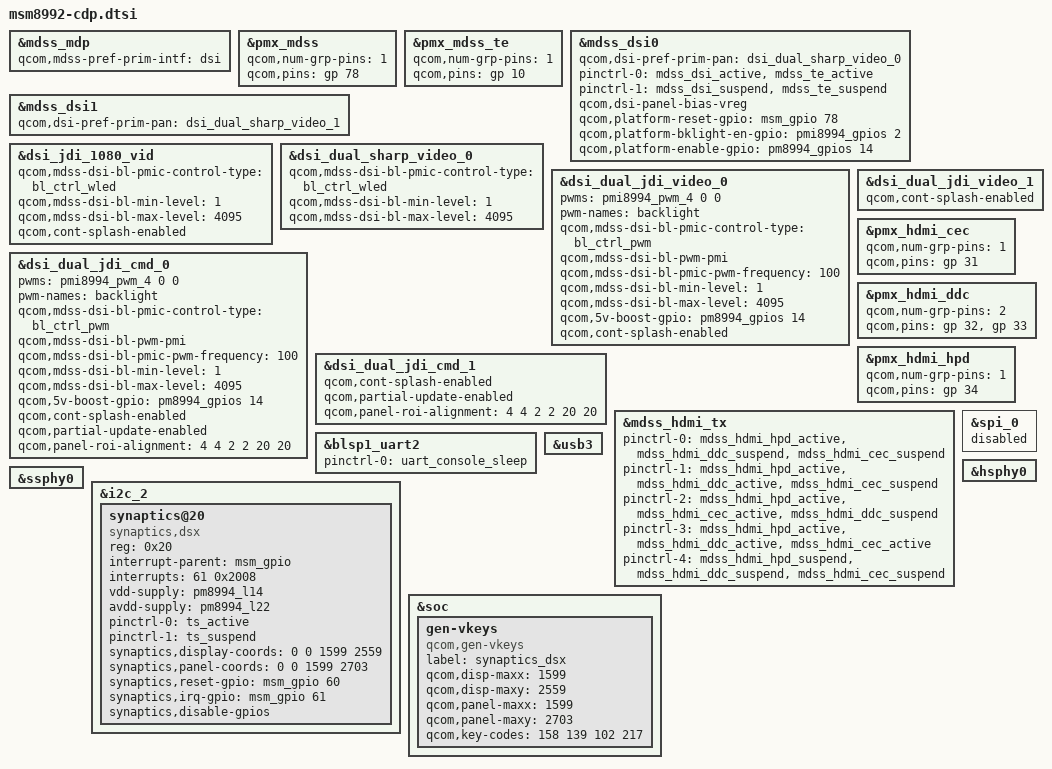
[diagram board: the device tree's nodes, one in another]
/* Copyright (c) 2014, The Linux Foundation. All rights reserved.
 *
 * This program is free software; you can redistribute it and/or modify
 * it under the terms of the GNU General Public License version 2 and
 * only version 2 as published by the Free Software Foundation.
 *
 * This program is distributed in the hope that it will be useful,
 * but WITHOUT ANY WARRANTY; without even the implied warranty of
 * MERCHANTABILITY or FITNESS FOR A PARTICULAR PURPOSE.  See the
 * GNU General Public License for more details.
 */

#include "msm8992-pinctrl.dtsi"

#include "dsi-panel-sharp-dualmipi0-wqxga-video.dtsi"
#include "dsi-panel-sharp-dualmipi1-wqxga-video.dtsi"
#include "dsi-panel-jdi-dualmipi0-video.dtsi"
#include "dsi-panel-jdi-dualmipi1-video.dtsi"
#include "dsi-panel-jdi-dualmipi0-cmd.dtsi"
#include "dsi-panel-jdi-dualmipi1-cmd.dtsi"
#include "dsi-panel-nt35597-wqxga-video.dtsi"
#include "dsi-panel-nt35597-wqxga-cmd.dtsi"
#include "dsi-panel-jdi-1080p-video.dtsi"

&mdss_mdp {
	qcom,mdss-pref-prim-intf = "dsi";
};

&pmx_mdss {
	qcom,num-grp-pins = <1>;
	qcom,pins = <&gp 78>;
};

&pmx_mdss_te {
	qcom,num-grp-pins = <1>;
	qcom,pins = <&gp 10>;
};

&mdss_dsi0 {
	qcom,dsi-pref-prim-pan = <&dsi_dual_sharp_video_0>;
	pinctrl-names = "mdss_default", "mdss_sleep";
	pinctrl-0 = <&mdss_dsi_active &mdss_te_active>;
	pinctrl-1 = <&mdss_dsi_suspend &mdss_te_suspend>;
	qcom,dsi-panel-bias-vreg;
	qcom,platform-reset-gpio = <&msm_gpio 78 0>;
	qcom,platform-bklight-en-gpio = <&pmi8994_gpios 2 0>;
	qcom,platform-enable-gpio = <&pm8994_gpios 14 0>;
};

&mdss_dsi1 {
	qcom,dsi-pref-prim-pan = <&dsi_dual_sharp_video_1>;
};

&dsi_jdi_1080_vid {
	qcom,mdss-dsi-bl-pmic-control-type = "bl_ctrl_wled";
	qcom,mdss-dsi-bl-min-level = <1>;
	qcom,mdss-dsi-bl-max-level = <4095>;
	qcom,cont-splash-enabled;
};

&dsi_dual_sharp_video_0 {
	qcom,mdss-dsi-bl-pmic-control-type = "bl_ctrl_wled";
	qcom,mdss-dsi-bl-min-level = <1>;
	qcom,mdss-dsi-bl-max-level = <4095>;
};

&dsi_dual_jdi_video_0 {
	pwms = <&pmi8994_pwm_4 0 0>;
	pwm-names = "backlight";
	qcom,mdss-dsi-bl-pmic-control-type = "bl_ctrl_pwm";
	qcom,mdss-dsi-bl-pwm-pmi;
	qcom,mdss-dsi-bl-pmic-pwm-frequency = <100>;
	qcom,mdss-dsi-bl-min-level = <1>;
	qcom,mdss-dsi-bl-max-level = <4095>;
	qcom,5v-boost-gpio = <&pm8994_gpios 14 0>;
	qcom,cont-splash-enabled;
};

&dsi_dual_jdi_video_1 {
	qcom,cont-splash-enabled;
};

&dsi_dual_jdi_cmd_0 {
	pwms = <&pmi8994_pwm_4 0 0>;
	pwm-names = "backlight";
	qcom,mdss-dsi-bl-pmic-control-type = "bl_ctrl_pwm";
	qcom,mdss-dsi-bl-pwm-pmi;
	qcom,mdss-dsi-bl-pmic-pwm-frequency = <100>;
	qcom,mdss-dsi-bl-min-level = <1>;
	qcom,mdss-dsi-bl-max-level = <4095>;
	qcom,5v-boost-gpio = <&pm8994_gpios 14 0>;
	qcom,cont-splash-enabled;
	qcom,partial-update-enabled;
	qcom,panel-roi-alignment = <4 4 2 2 20 20>;
};

&dsi_dual_jdi_cmd_1 {
	qcom,cont-splash-enabled;
	qcom,partial-update-enabled;
	qcom,panel-roi-alignment = <4 4 2 2 20 20>;
};

&pmx_hdmi_cec {
	qcom,num-grp-pins = <1>;
	qcom,pins = <&gp 31>;
};

&pmx_hdmi_ddc {
	qcom,num-grp-pins = <2>;
	qcom,pins = <&gp 32>, <&gp 33>;
};

&pmx_hdmi_hpd {
	qcom,num-grp-pins = <1>;
	qcom,pins = <&gp 34>;
};

&mdss_hdmi_tx {
	pinctrl-names = "hdmi_hpd_active", "hdmi_ddc_active",
				"hdmi_cec_active", "hdmi_active",
				"hdmi_sleep";
	pinctrl-0 = <&mdss_hdmi_hpd_active &mdss_hdmi_ddc_suspend
						&mdss_hdmi_cec_suspend>;
	pinctrl-1 = <&mdss_hdmi_hpd_active &mdss_hdmi_ddc_active
						&mdss_hdmi_cec_suspend>;
	pinctrl-2 = <&mdss_hdmi_hpd_active &mdss_hdmi_cec_active
						&mdss_hdmi_ddc_suspend>;
	pinctrl-3 = <&mdss_hdmi_hpd_active &mdss_hdmi_ddc_active
						&mdss_hdmi_cec_active>;
	pinctrl-4 = <&mdss_hdmi_hpd_suspend &mdss_hdmi_ddc_suspend
						&mdss_hdmi_cec_suspend>;
};
&blsp1_uart2 {
	status= "ok";
	pinctrl-names = "default";
	pinctrl-0 = <&uart_console_sleep>;
};

&spi_0 {
	status = "disabled";
};

&usb3 {
	status = "ok";
};

&hsphy0 {
	status = "ok";
};

&ssphy0 {
	status = "ok";
};

&i2c_2 {
	synaptics@20 {
		compatible = "synaptics,dsx";
		reg = <0x20>;
		interrupt-parent = <&msm_gpio>;
		interrupts = <61 0x2008>;
		vdd-supply = <&pm8994_l14>;
		avdd-supply = <&pm8994_l22>;
		pinctrl-names = "pmx_ts_active", "pmx_ts_suspend";
		pinctrl-0 = <&ts_active>;
		pinctrl-1 = <&ts_suspend>;
		synaptics,display-coords = <0 0 1599 2559>;
		synaptics,panel-coords = <0 0 1599 2703>;
		synaptics,reset-gpio = <&msm_gpio 60 0x00>;
		synaptics,irq-gpio = <&msm_gpio 61 0x00>;
		synaptics,disable-gpios;
	};
};

&soc {
	gen-vkeys {
		compatible = "qcom,gen-vkeys";
		label = "synaptics_dsx";
		qcom,disp-maxx = <1599>;
		qcom,disp-maxy = <2559>;
		qcom,panel-maxx = <1599>;
		qcom,panel-maxy = <2703>;
		qcom,key-codes = <158 139 102 217>;
	};
};
